# NANO112AN_v1 register map
File version: 1.0
Registers are 32-bit, read-write, reset 0x0 unless marked. A register's access mark holds for its fields unless they carry their own. Offsets are from the block's base; [hi:lo] are bit positions; {n}, {i} and the like mark numbered series.

## LCD — LCD Register Map
Base 0x400B0000
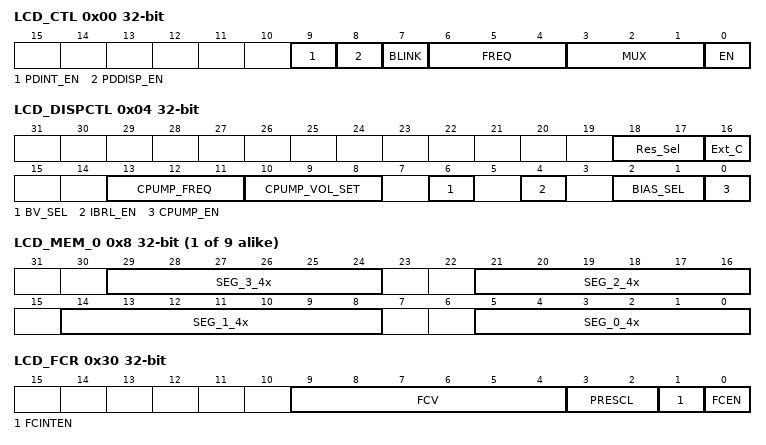
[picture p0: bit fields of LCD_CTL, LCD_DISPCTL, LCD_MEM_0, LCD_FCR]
0x00 LCD_CTL — LCD Control Register
  [9] PDINT_EN — Power Down Interrupt Enable Control. If the power down request is triggered from system management, LCD controller will execute the frame completely to avoid the DC component. When the frame is executed completely, the LCD power down interrupt signal is generated to inform system management that LCD controller is ready to enter power down state, if PDINT_EN is set to 1. Otherwise, if PDINT_EN is set to 0, the LCD power down interrupt signal is blocked and the interrupt is disabled to send to system management.
    0=Power Down Interrupt Disabled; 1=Power Down Interrupt Enabled
  [8] PDDISP_EN — Power Down Display Enable Control. The LCD can be programmed to be displayed or not be displayed at power down state by PDDISP_EN setting.
    0=LCD display Disabled ( LCD is put out) at power down state; 1=LCD display Enabled (LCD keeps the display) at power down state
  [7] BLINK — LCD Blinking Enable Control
    0=Blinking Disabled; 1=Blinking Enabled
  [6:4] FREQ — LCD Frequency Selection
    0=LCD_CLK Divided by 32; 1=LCD_CLK Divided by 64; 2=LCD_CLK Divided by 96; 3=LCD_CLK Divided by 128; 4=LCD_CLK Divided by 192; 5=LCD_CLK Divided by 256; 6=LCD_CLK Divided by 384; 7=LCD_CLK Divided by 512
  [3:1] MUX — Mux Select
    0=Static; {v}=1/{v+1} duty (v=1..5)
  [0] EN — LCD Enable Control
    0=LCD controller operation Disabled; 1=LCD controller operation Enabled
0x04 LCD_DISPCTL — LCD Display Control Register
  [18:17] Res_Sel — R-type Resistor Value Selection. The LCD operation current will be different when we select different R-type resistor value.
    0=200K Ohm; 1=300K Ohm; 3=400K Ohm
  [16] Ext_C — Ext_C Mode Selection. This mode is similar to C-type LCD mode, but the operation current is lower than C-type mode. The control register setting is same with C-type mode except this bit is set to "1".
    0=Disable; 1=Enable
  [13:11] CPUMP_FREQ — Charge Pump Frequency Selection
    0=LCD_CLK; 1=LCD_CLK/2; 2=LCD_CLK/4; 3=LCD_CLK/8; 4=LCD_CLK/16; 5=LCD_CLK/32; 6=LCD_CLK/64; 7=LCD_CLK/128
  [10:8] CPUMP_VOL_SET — Charge Pump Voltage Selection
    0=2.7V; 1=2.8V; 2=2.9V; 3=3.0V; 4=3.1V; 5=3.2V; 6=3.3V; 7=3.4V
  [6] BV_SEL — Bias Voltage Type Selection. Note: The external resistor ladder should be connected to the V1 pin, V2 pin, V3 pin and VSS. The VLCD pin should also be connected to VDD.
    0=C-Type bias mode. Bias voltage source from internal bias generator; 1=R-Type bias mode. Bias voltage source from external bias generator
  [4] IBRL_EN — Internal Bias Reference Ladder Enable Control
    0=Bias reference ladder Disabled; 1=Bias reference ladder Dnabled
  [2:1] BIAS_SEL — Bias Selection
    0=Static; 1=1/2 Bias; 2=1/3 Bias
  [0] CPUMP_EN — Charge Pump Enable Control
    0=Disabled; 1=Enabled
{0x8+4i} LCD_MEM_{i} (i=0..8) — LCD SEG{4i+3} ~ SEG{4i} Data
  [29:24] SEG_3_4x — For the LCD Display Memory MAP, please refer to Figure 6-54.
  [21:16] SEG_2_4x — For the LCD Display Memory MAP, please refer to Figure 6-54.
  [14:8] SEG_1_4x — For the LCD Display Memory MAP, please refer to Figure 6-54.
  [5:0] SEG_0_4x — For the LCD Display Memory MAP, please refer to Figure 6-54.
0x30 LCD_FCR — LCD Frame Counter Control Register
  [9:4] FCV — Frame Counter Top Value. These 6 bits contain the top value of the Frame counter.
  [3:2] PRESCL — Frame Counter Pre-scaler Value
    0=CLKframe/1; 1=CLKframe/2; 2=CLKframe/4; 3=CLKframe/8
  [1] FCINTEN — LCD Frame Counter Interrupt Enable Control
    0=Frame counter interrupt Disabled; 1=Frame counter interrupt Enabled
  [0] FCEN — LCD Frame Counter Enable Control
    0=Disabled; 1=Enabled
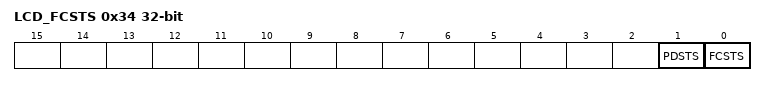
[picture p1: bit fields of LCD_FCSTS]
0x34 LCD_FCSTS — LCD Frame Counter Status
  [1] PDSTS — Power-down Interrupt Status
    0=Inform system manager that LCD controller is not ready to enter power-down state until this bit becomes 1 if power down is set and one frame is not executed completely; 1=Inform system manager that LCD controller is ready to enter power-down state if power down is set and one frame is executed completely
  [0] FCSTS — LCD Frame Counter Status
    0=Frame counter value does not reach FCV (Frame Count TOP value); 1=Frame counter value reaches FCV (Frame Count TOP value). If the FCINTEN is s enabled, the frame counter overflow Interrupt is generated
